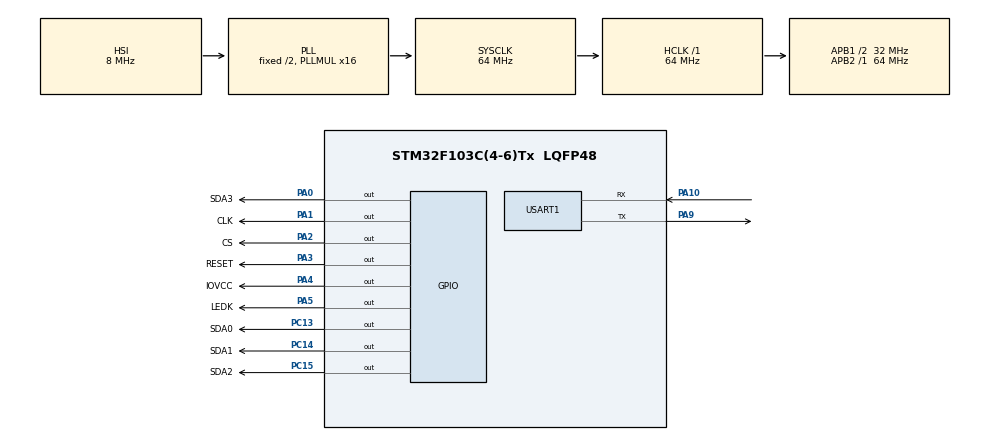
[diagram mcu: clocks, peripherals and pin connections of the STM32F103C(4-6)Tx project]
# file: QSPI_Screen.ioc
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Mcu.Family=STM32F1
Mcu.Name=STM32F103C(4-6)Tx
Mcu.Package=LQFP48
NVIC.PriorityGroup=NVIC_PRIORITYGROUP_4
PA0-WKUP.GPIO_Label=SDA3
PA0-WKUP.Signal=GPIO_Output
PA1.GPIO_Label=CLK
PA1.Signal=GPIO_Output
PA10.Mode=Asynchronous
PA10.Signal=USART1_RX
PA2.GPIO_Label=CS
PA2.Signal=GPIO_Output
PA3.GPIO_Label=RESET
PA3.Signal=GPIO_Output
PA4.GPIO_Label=IOVCC
PA4.Signal=GPIO_Output
PA5.GPIO_Label=LEDK
PA5.Signal=GPIO_Output
PA9.Mode=Asynchronous
PA9.Signal=USART1_TX
PC13-TAMPER-RTC.GPIO_Label=SDA0
PC13-TAMPER-RTC.Signal=GPIO_Output
PC14-OSC32_IN.GPIO_Label=SDA1
PC14-OSC32_IN.Signal=GPIO_Output
PC15-OSC32_OUT.GPIO_Label=SDA2
PC15-OSC32_OUT.Signal=GPIO_Output
ProjectManager.HeapSize=0x200
ProjectManager.StackSize=0x400
ProjectManager.TargetToolchain=MDK-ARM V5.32
RCC.AHBFreq_Value=64000000
RCC.APB1CLKDivider=RCC_HCLK_DIV2
RCC.APB1Freq_Value=32000000
RCC.APB1TimFreq_Value=64000000
RCC.APB2Freq_Value=64000000
RCC.APB2TimFreq_Value=64000000
RCC.HCLKFreq_Value=64000000
RCC.PLLMUL=RCC_PLL_MUL16
RCC.SYSCLKFreq_VALUE=64000000
RCC.SYSCLKSource=RCC_SYSCLKSOURCE_PLLCLK
RCC.USBFreq_Value=64000000
TIM3.Period=0
TIM3.Prescaler=63
USART1.VirtualMode=VM_ASYNC
VP_SYS_VS_ND.Mode=No_Debug
VP_TIM3_VS_ClockSourceINT.Mode=Internal
board=custom

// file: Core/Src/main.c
/* USER CODE BEGIN Header */
/**
  ******************************************************************************
  * @file           : main.c
  * @brief          : Main program body
  ******************************************************************************
  * @attention
  *
  * Copyright (c) 2023 STMicroelectronics.
  * All rights reserved.
  *
  * This software is licensed under terms that can be found in the LICENSE file
  * in the root directory of this software component.
  * If no LICENSE file comes with this software, it is provided AS-IS.
  *
  ******************************************************************************
  */
/* USER CODE END Header */
#include "main.h"
#include "tim.h"
#include "usart.h"
#include "gpio.h"

/* USER CODE BEGIN Includes */
#include "../Bsp/bsp_qspi.h "
#include <stdio.h>
/* USER CODE END Includes */

void SystemClock_Config(void);

int main(void)
{

  /* MCU Configuration--------------------------------------------------------*/

  /* Reset of all peripherals, Initializes the Flash interface and the Systick. */
  HAL_Init();

  /* Configure the system clock */
  SystemClock_Config();

  /* Initialize all configured peripherals */
  MX_GPIO_Init();
  MX_TIM3_Init();
  MX_USART1_UART_Init();

  /* Infinite loop */
  /* USER CODE BEGIN WHILE */

	Init_LCD();
	BlockWrite(0, 320, 0, 320);
	printf("init ok now start\r\n");
	while(1);

  while (1)
  {
    /* USER CODE END WHILE */

  }
}

void SystemClock_Config(void)
{
  RCC_OscInitTypeDef RCC_OscInitStruct = {0};
  RCC_ClkInitTypeDef RCC_ClkInitStruct = {0};

  /** Initializes the RCC Oscillators according to the specified parameters
  * in the RCC_OscInitTypeDef structure.
  */
  RCC_OscInitStruct.OscillatorType = RCC_OSCILLATORTYPE_HSI;
  RCC_OscInitStruct.HSIState = RCC_HSI_ON;
  RCC_OscInitStruct.HSICalibrationValue = RCC_HSICALIBRATION_DEFAULT;
  RCC_OscInitStruct.PLL.PLLState = RCC_PLL_ON;
  RCC_OscInitStruct.PLL.PLLSource = RCC_PLLSOURCE_HSI_DIV2;
  RCC_OscInitStruct.PLL.PLLMUL = RCC_PLL_MUL16;
  if (HAL_RCC_OscConfig(&RCC_OscInitStruct) != HAL_OK)
  {
    Error_Handler();
  }

  /** Initializes the CPU, AHB and APB buses clocks
  */
  RCC_ClkInitStruct.ClockType = RCC_CLOCKTYPE_HCLK|RCC_CLOCKTYPE_SYSCLK
                              |RCC_CLOCKTYPE_PCLK1|RCC_CLOCKTYPE_PCLK2;
  RCC_ClkInitStruct.SYSCLKSource = RCC_SYSCLKSOURCE_PLLCLK;
  RCC_ClkInitStruct.AHBCLKDivider = RCC_SYSCLK_DIV1;
  RCC_ClkInitStruct.APB1CLKDivider = RCC_HCLK_DIV2;
  RCC_ClkInitStruct.APB2CLKDivider = RCC_HCLK_DIV1;

  if (HAL_RCC_ClockConfig(&RCC_ClkInitStruct, FLASH_LATENCY_2) != HAL_OK)
  {
    Error_Handler();
  }
}

void Error_Handler(void)
{
  __disable_irq();
  while (1)
  {
  }
}
